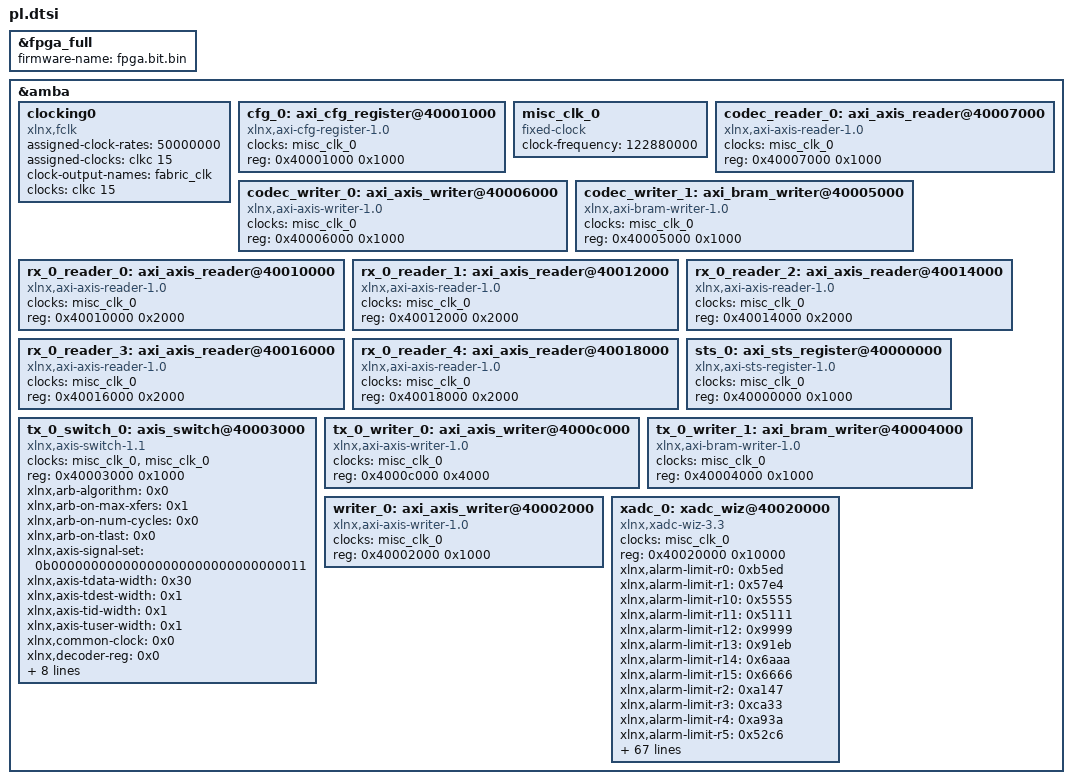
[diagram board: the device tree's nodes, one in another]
/*
 * CAUTION: This file is automatically generated by Xilinx.
 * Version:  
 * Today is: Thu May  4 15:50:34 2023
 */


/dts-v1/;
/plugin/;
/ {
	fragment@0 {
		target = <&fpga_full>;
		overlay0: __overlay__ {
			//#address-cells = <2>;
			//#size-cells = <2>;
			firmware-name = "fpga.bit.bin";
		};
	};
	fragment@1 {
		target = <&amba>;
		overlay1: __overlay__ {
			clocking0: clocking0 {
				#clock-cells = <0>;
				assigned-clock-rates = <50000000>;
				assigned-clocks = <&clkc 15>;
				clock-output-names = "fabric_clk";
				clocks = <&clkc 15>;
				compatible = "xlnx,fclk";
			};
		};
	};
	fragment@2 {
		target = <&amba>;
		overlay2: __overlay__ {
			//#address-cells = <1>;
			//#size-cells = <1>;
			cfg_0: axi_cfg_register@40001000 {
				clock-names = "aclk";
				clocks = <&misc_clk_0>;
				compatible = "xlnx,axi-cfg-register-1.0";
				reg = <0x40001000 0x1000>;
			};
			misc_clk_0: misc_clk_0 {
				#clock-cells = <0>;
				clock-frequency = <122880000>;
				compatible = "fixed-clock";
			};
			codec_reader_0: axi_axis_reader@40007000 {
				clock-names = "aclk";
				clocks = <&misc_clk_0>;
				compatible = "xlnx,axi-axis-reader-1.0";
				reg = <0x40007000 0x1000>;
			};
			codec_writer_0: axi_axis_writer@40006000 {
				clock-names = "aclk";
				clocks = <&misc_clk_0>;
				compatible = "xlnx,axi-axis-writer-1.0";
				reg = <0x40006000 0x1000>;
			};
			codec_writer_1: axi_bram_writer@40005000 {
				clock-names = "aclk";
				clocks = <&misc_clk_0>;
				compatible = "xlnx,axi-bram-writer-1.0";
				reg = <0x40005000 0x1000>;
			};
			rx_0_reader_0: axi_axis_reader@40010000 {
				clock-names = "aclk";
				clocks = <&misc_clk_0>;
				compatible = "xlnx,axi-axis-reader-1.0";
				reg = <0x40010000 0x2000>;
			};
			rx_0_reader_1: axi_axis_reader@40012000 {
				clock-names = "aclk";
				clocks = <&misc_clk_0>;
				compatible = "xlnx,axi-axis-reader-1.0";
				reg = <0x40012000 0x2000>;
			};
			rx_0_reader_2: axi_axis_reader@40014000 {
				clock-names = "aclk";
				clocks = <&misc_clk_0>;
				compatible = "xlnx,axi-axis-reader-1.0";
				reg = <0x40014000 0x2000>;
			};
			rx_0_reader_3: axi_axis_reader@40016000 {
				clock-names = "aclk";
				clocks = <&misc_clk_0>;
				compatible = "xlnx,axi-axis-reader-1.0";
				reg = <0x40016000 0x2000>;
			};
			rx_0_reader_4: axi_axis_reader@40018000 {
				clock-names = "aclk";
				clocks = <&misc_clk_0>;
				compatible = "xlnx,axi-axis-reader-1.0";
				reg = <0x40018000 0x2000>;
			};
			sts_0: axi_sts_register@40000000 {
				clock-names = "aclk";
				clocks = <&misc_clk_0>;
				compatible = "xlnx,axi-sts-register-1.0";
				reg = <0x40000000 0x1000>;
			};
			tx_0_switch_0: axis_switch@40003000 {
				clock-names = "aclk", "s_axi_ctrl_aclk";
				clocks = <&misc_clk_0>, <&misc_clk_0>;
				compatible = "xlnx,axis-switch-1.1";
				reg = <0x40003000 0x1000>;
				xlnx,arb-algorithm = <0x0>;
				xlnx,arb-on-max-xfers = <0x1>;
				xlnx,arb-on-num-cycles = <0x0>;
				xlnx,arb-on-tlast = <0x0>;
				xlnx,axis-signal-set = "0b00000000000000000000000000000011";
				xlnx,axis-tdata-width = <0x30>;
				xlnx,axis-tdest-width = <0x1>;
				xlnx,axis-tid-width = <0x1>;
				xlnx,axis-tuser-width = <0x1>;
				xlnx,common-clock = <0x0>;
				xlnx,decoder-reg = <0x0>;
				xlnx,include-arbiter = <0x1>;
				xlnx,log-si-slots = <0x1>;
				xlnx,num-mi-slots = <0x1>;
				xlnx,num-si-slots = <0x2>;
				xlnx,output-reg = <0x0>;
				xlnx,routing-mode = <0x1>;
				xlnx,s-axi-ctrl-addr-width = <0x7>;
				xlnx,s-axi-ctrl-data-width = <0x20>;
			};
			tx_0_writer_0: axi_axis_writer@4000c000 {
				clock-names = "aclk";
				clocks = <&misc_clk_0>;
				compatible = "xlnx,axi-axis-writer-1.0";
				reg = <0x4000c000 0x4000>;
			};
			tx_0_writer_1: axi_bram_writer@40004000 {
				clock-names = "aclk";
				clocks = <&misc_clk_0>;
				compatible = "xlnx,axi-bram-writer-1.0";
				reg = <0x40004000 0x1000>;
			};
			writer_0: axi_axis_writer@40002000 {
				clock-names = "aclk";
				clocks = <&misc_clk_0>;
				compatible = "xlnx,axi-axis-writer-1.0";
				reg = <0x40002000 0x1000>;
			};
			xadc_0: xadc_wiz@40020000 {
				clock-names = "s_axi_aclk";
				clocks = <&misc_clk_0>;
				compatible = "xlnx,xadc-wiz-3.3", "xlnx,axi-xadc-1.00.a";
				reg = <0x40020000 0x10000>;
				xlnx,alarm-limit-r0 = <0xb5ed>;
				xlnx,alarm-limit-r1 = <0x57e4>;
				xlnx,alarm-limit-r10 = <0x5555>;
				xlnx,alarm-limit-r11 = <0x5111>;
				xlnx,alarm-limit-r12 = <0x9999>;
				xlnx,alarm-limit-r13 = <0x91eb>;
				xlnx,alarm-limit-r14 = <0x6aaa>;
				xlnx,alarm-limit-r15 = <0x6666>;
				xlnx,alarm-limit-r2 = <0xa147>;
				xlnx,alarm-limit-r3 = <0xca33>;
				xlnx,alarm-limit-r4 = <0xa93a>;
				xlnx,alarm-limit-r5 = <0x52c6>;
				xlnx,alarm-limit-r6 = <0x9555>;
				xlnx,alarm-limit-r7 = <0xae4e>;
				xlnx,alarm-limit-r8 = <0x5999>;
				xlnx,alarm-limit-r9 = <0x5111>;
				xlnx,configuration-r0 = <0x0>;
				xlnx,configuration-r1 = <0x8100>;
				xlnx,configuration-r2 = <0x1800>;
				xlnx,dclk-frequency = <0x7a>;
				xlnx,external-mux = "none";
				xlnx,external-mux-channel = "VP_VN";
				xlnx,external-muxaddr-enable = <0x0>;
				xlnx,fifo-depth = <0x7>;
				xlnx,has-axi = <0x1>;
				xlnx,has-axi4stream = <0x0>;
				xlnx,has-busy = <0x1>;
				xlnx,has-channel = <0x1>;
				xlnx,has-convst = <0x0>;
				xlnx,has-convstclk = <0x0>;
				xlnx,has-dclk = <0x1>;
				xlnx,has-drp = <0x0>;
				xlnx,has-eoc = <0x1>;
				xlnx,has-eos = <0x1>;
				xlnx,has-external-mux = <0x0>;
				xlnx,has-jtagbusy = <0x0>;
				xlnx,has-jtaglocked = <0x0>;
				xlnx,has-jtagmodified = <0x0>;
				xlnx,has-ot-alarm = <0x1>;
				xlnx,has-reset = <0x0>;
				xlnx,has-temp-bus = <0x0>;
				xlnx,has-user-temp-alarm = <0x1>;
				xlnx,has-vbram-alarm = <0x0>;
				xlnx,has-vccaux-alarm = <0x1>;
				xlnx,has-vccddro-alarm = <0x1>;
				xlnx,has-vccint-alarm = <0x1>;
				xlnx,has-vccpaux-alarm = <0x1>;
				xlnx,has-vccpint-alarm = <0x1>;
				xlnx,has-vn = <0x1>;
				xlnx,has-vp = <0x1>;
				xlnx,include-intr = <0x1>;
				xlnx,sampling-rate = "196923.07692307694";
				xlnx,sequence-r0 = <0x800>;
				xlnx,sequence-r1 = <0x303>;
				xlnx,sequence-r2 = <0x0>;
				xlnx,sequence-r3 = <0x0>;
				xlnx,sequence-r4 = <0x0>;
				xlnx,sequence-r5 = <0x0>;
				xlnx,sequence-r6 = <0x0>;
				xlnx,sequence-r7 = <0x0>;
				xlnx,sim-file-name = "design";
				xlnx,sim-file-rel-path = "./";
				xlnx,sim-file-sel = "Default";
				xlnx,vaux0 = <0x1>;
				xlnx,vaux1 = <0x1>;
				xlnx,vaux10 = <0x0>;
				xlnx,vaux11 = <0x0>;
				xlnx,vaux12 = <0x0>;
				xlnx,vaux13 = <0x0>;
				xlnx,vaux14 = <0x0>;
				xlnx,vaux15 = <0x0>;
				xlnx,vaux2 = <0x0>;
				xlnx,vaux3 = <0x0>;
				xlnx,vaux4 = <0x0>;
				xlnx,vaux5 = <0x0>;
				xlnx,vaux6 = <0x0>;
				xlnx,vaux7 = <0x0>;
				xlnx,vaux8 = <0x1>;
				xlnx,vaux9 = <0x1>;
			};
		};
	};
};
